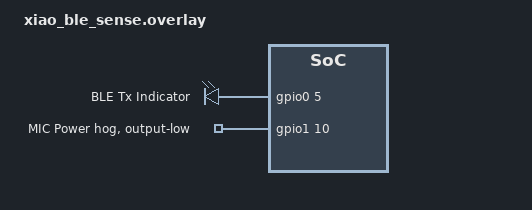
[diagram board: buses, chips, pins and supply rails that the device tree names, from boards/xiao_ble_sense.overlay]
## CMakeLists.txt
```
# SPDX-License-Identifier: MIT
cmake_minimum_required(VERSION 3.20)
find_package(Zephyr REQUIRED HINTS $ENV{ZEPHYR_BASE})
project(bthome_imu)
target_sources(app PRIVATE src/main.c)
```

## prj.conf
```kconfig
# ── Bluetooth ──────────────────────────────────────────────────────────────
CONFIG_BT=y
CONFIG_BT_PERIPHERAL=y
CONFIG_BT_DEVICE_NAME="MAKE-IMU"
# bt_disable() wird im Low-Power-Loop genutzt (kein CTRL_DISABLE-Flag nötig)

# ── BThome V2 library ───────────────────────────────────────────────────────
CONFIG_BTHOME_V2=y

# ── Sensor framework ────────────────────────────────────────────────────────
CONFIG_SENSOR=y
CONFIG_I2C=y
CONFIG_LSM6DSL=y
CONFIG_LSM6DSL_ACCEL_ODR=4
CONFIG_LSM6DSL_GYRO_ODR=4

# ── Logging ─────────────────────────────────────────────────────────────────
CONFIG_LOG=y
CONFIG_LOG_MODE_IMMEDIATE=y

# ── Stack ────────────────────────────────────────────────────────────────────
# bt_enable()/bt_disable() im Loop braucht etwas mehr Stack als einmalige Init
CONFIG_MAIN_STACK_SIZE=3072
CONFIG_BT_RX_STACK_SIZE=1024
CONFIG_IDLE_STACK_SIZE=512

# ── Power Management ─────────────────────────────────────────────────────────
# PM_DEVICE: für IMU SUSPEND/RESUME via pm_device_action_run()
CONFIG_PM_DEVICE=y
# KEIN PM_DEVICE_RUNTIME: würde Work-Queue-Threads erzeugen → Stack-Overhead
CONFIG_PM_DEVICE_RUNTIME=n
# Tickless Kernel: nRF52840 schläft in WFE während k_sleep() → ~3 µA SoC
CONFIG_TICKLESS_KERNEL=y
```

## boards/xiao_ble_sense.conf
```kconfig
# XIAO nRF52840 Sense — board-specific config for 200_bthome_imu

# ── LFCLK: RC-Oszillator ─────────────────────────────────────────────────────
# XIAO nRF52840 hat keinen externen 32.768-kHz-Quarz → RC-Oszillator ist Pflicht.
CONFIG_CLOCK_CONTROL_NRF_K32SRC_RC=y

# ── Serial / USB / Log: ausschalten für Batteriebetrieb ──────────────────────────
#
# Das Board-Defconfig (xiao_ble_defconfig) aktiviert USB + UART + CONSOLE.
# Alle drei halten den HFCLK und müssen deaktiviert werden:
#
#   USB_DEVICE_STACK=y  → ~1.1 mA  (USB-SOF-IRQ alle 1 ms hält HFXO)
#   SERIAL=y            → ~1.0 mA  (UARTE0 hält den HFINT-Oszillator)
#
CONFIG_USB_DEVICE_STACK=n
CONFIG_USB_CDC_ACM=n
CONFIG_SERIAL=n
CONFIG_CONSOLE=n
CONFIG_UART_CONSOLE=n
CONFIG_LOG=n

# ── MPSL / HFCLK – wichtiger Hinweis ───────────────────────────────────────────
# CONFIG_BT_UNINIT_MPSL_ON_DISABLE wird hier NICHT gesetzt!
#
# Dieses Sample nutzt System ON / CPU asleep (WFI), KEIN System OFF.
# BT_UNINIT_MPSL_ON_DISABLE ruft mpsl_lib_uninit() auf, was den MPSL-Clock-
# Arbiter entfernt. Wenn danach die Zephyr-RC-Kalibrierung (~alle 4 s) feuert,
# gibt es keinen Arbiter mehr → HFCLK bleibt dauerhaft aktiv → ~400 µA Floor.
#
# Ohne BT_UNINIT_MPSL_ON_DISABLE: bt_disable() gibt HFCLK frei, MPSL bleibt
# initialisiert und verwaltet die RC-Kalibrierung korrekt.
# Ergebnis: CPU im WFI-Sleep → ~10–45 µA.

# ── NFCT-Pins als GPIO freigeben ─────────────────────────────────────────────
CONFIG_NFCT_PINS_AS_GPIOS=y

# ── GPIO-Regulator für IMU-Stromversorgung (P1.08) ───────────────────────────
CONFIG_REGULATOR=y

# ── BLE TX-Leistung begrenzen ─────────────────────────────────────────────────
# −20 dBm genügt für Heimanwendungen (≈10 m), spart ~1.5 mA vs. 0 dBm.
CONFIG_BT_CTLR_TX_PWR_MINUS_20=y
```

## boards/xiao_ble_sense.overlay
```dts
/* DTS-Overlay für Seeed XIAO nRF52840 Sense
 * Fügt einen imu0-Alias hinzu, damit main.c board-unabhängig bleibt.
 */
/ {
	aliases {
		imu0 = &lsm6ds3tr_c;
	};
};

/* ── QSPI-Flash: Peripheral deaktivieren ────────────────────────────────────
 * nrfx_qspi_init() hält HFCLK permanent (~200 µA im Leerlauf).
 * Bit-Bang DPD (0xB9) wird in main.c vor bt_enable() gesendet.
 * Der Flash bleibt danach in Deep Power-Down bis zum nächsten Power-Cycle. */
&qspi {
	status = "disabled";
};

/* ── Active Indicator: P0.05 (XIAO D5 / i2c1 SCL) ──────────────────────────────────
 * HIGH während des BLE-ADV-Fensters, LOW im Schlaf.
 * i2c1 (P0.04=SDA, P0.05=SCL) muss deaktiviert werden, um P0.05 als GPIO zu nutzen. */
&i2c1 {
	status = "disabled";
};

/ {
	active_ind: active_indicator {
		compatible = "gpio-leds";
		active0: active_0 {
			gpios = <&gpio0 5 GPIO_ACTIVE_HIGH>;
			label = "BLE Tx Indicator";
		};
	};

	aliases {
		active-indicator = &active0;
	};
};

/* ── Mikrofon-Versorgung abschalten (P1.10) ──────────────────────────────────────────
 * P1.10 = VCC_MIC Enable (active-HIGH). LOW = Mikrofon ausgeschaltet.
 * gpio-hog setzt den Pin beim Boot auf LOW → Mikrofon bleibt dauerhaft aus. */
&gpio1 {
	pwr-mic {
		gpio-hog;
		gpios = <10 GPIO_ACTIVE_HIGH>;
		output-low;
		line-name = "MIC Power";
	};
};
```

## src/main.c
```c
/* SPDX-License-Identifier: MIT */
/*
 * Copyright (c) 2026 Daniel Glaser
 *
 * BThome V2 IMU Sample
 * ====================
 * Liest den eingebauten 6-Achsen-IMU (LSM6DS3TR-C) des Seeed XIAO
 * nRF52840 Sense und sendet Beschleunigung (X/Y/Z) und Gyroskop (Z)
 * alle 5 Sekunden als BThome-V2-Advertising.
 *
 * Zwei sequenzielle BThome-Pakete (je ADV_BURST_MS/2 = 500 ms):
 *   Paket 1 — Objekte (ASC):
 *     0x00  Packet ID           uint8              2 B
 *     0x52  Gyroscope           uint16  0.001 °/s  3 B   Gesamt: 5 B
 *   Paket 2 — Objekte (ASC):
 *     0x00  Packet ID           uint8              2 B
 *     0x63  Acceleration axis   sint32  0.000001 m/s²   (3×) 15 B  Gesamt: 17 B
 *
 * Hintergrund: Ältere bthome-ble-Versionen in HA haben Probleme mit
 * dreifachen 0x63-Einträgen im selben Paket. Splitting umgeht das Problem:
 * HA legt das Gerät via Paket 1 (bekannte IDs) an, Paket 2 ergänzt die
 * Accel-Entities. Beide Pakete werden über die MAC-Adresse verknüpft.
 *
 * Takt:
 *   IMU aktiv → fetch → Paket 1 (500 ms) → Paket 2 (500 ms) → sleep 4 s
 *   Netto-Zykluszeit ≈ 5 s
 *
 * Sensor-Konvertierung:
 *   Beschleunigung: Zephyr sensor_value (m/s²) → sint32 (µm/s² = × 1e6)
 *   Gyroskop:       Zephyr sensor_value (rad/s) → uint16 (mdeg/s)
 *                   Formel: |val_urad/s| × 180000 / 3141593
 *
 * Build:
 *   west build -b xiao_ble_sense samples/200_bthome_imu
 *   oder: make 200-build BOARD=xiao_ble_sense
 */

#include <zephyr/kernel.h>
#include <zephyr/logging/log.h>
#include <zephyr/bluetooth/bluetooth.h>
#include <zephyr/bluetooth/hci.h>
#include <zephyr/drivers/gpio.h>
#include <zephyr/drivers/sensor.h>
#include <zephyr/pm/device.h>
#include <hal/nrf_gpio.h>
#include <math.h>

#include <bthome_v2/bthome_v2.h>

LOG_MODULE_REGISTER(bthome_imu, LOG_LEVEL_INF);

/* ── IMU-Regulator-Startup-Delay ────────────────────────────────────────
 * Der regulator-fixed-Treiber setzt P1.08 HIGH während regulator_fixed_init()
 * (SYS_INIT POST_KERNEL, Prio 75). In der regulator-boot-on-Code-Pfad wird
 * startup-delay-us NICHT abgewartet (nur im api->enable()-Pfad). Der
 * LSM6DSL-Treiber (Prio 90) würde sonst unmittelbar danach starten, bevor
 * der IMU die 3 ms Hochlaufzeit abgeschlossen hat.
 *
 * Lösung: SYS_INIT bei Prio 80 wartet 5 ms, bevor der Sensor-Treiber
 * bei Prio 90 initialisiert wird.
 */
static int imu_power_on_delay(void)
{
	/* 5 ms busy-wait: sicherer als k_sleep() während POST_KERNEL-Init */
	k_busy_wait(5000U);
	return 0;
}
SYS_INIT(imu_power_on_delay, POST_KERNEL, 80);

/* ── P25Q16H QSPI-Flash Deep Power-Down via GPIO Bit-Bang ──────────────── */
#define FLASH_PIN_MOSI  20u
#define FLASH_PIN_SCK   21u
#define FLASH_PIN_CSN   25u
#define FLASH_CMD_DPD   0xB9u

static void flash_deep_power_down(void)
{
	nrf_gpio_cfg_output(FLASH_PIN_CSN);
	nrf_gpio_cfg_output(FLASH_PIN_SCK);
	nrf_gpio_cfg_output(FLASH_PIN_MOSI);
	nrf_gpio_pin_set(FLASH_PIN_CSN);
	nrf_gpio_pin_clear(FLASH_PIN_SCK);
	nrf_gpio_pin_clear(FLASH_PIN_MOSI);
	nrf_gpio_pin_clear(FLASH_PIN_CSN);
	for (int i = 7; i >= 0; i--) {
		nrf_gpio_pin_write(FLASH_PIN_MOSI, (FLASH_CMD_DPD >> i) & 1u);
		nrf_gpio_pin_set(FLASH_PIN_SCK);
		nrf_gpio_pin_clear(FLASH_PIN_SCK);
	}
	nrf_gpio_pin_set(FLASH_PIN_CSN);
	k_busy_wait(10u);
}

/* ── IMU-Gerät ─────────────────────────────────────────────────────────── */
#if DT_NODE_HAS_STATUS(DT_ALIAS(imu0), okay)
static const struct device *const imu = DEVICE_DT_GET(DT_ALIAS(imu0));
#define HAS_IMU 1
#else
#define HAS_IMU 0
#warning "kein imu0-Alias definiert – Sensor-Ausgabe wird simuliert"
#endif

/* ── Active Indicator (P0.05 = D5): HIGH während BLE aktiv ─────────────── */
#if DT_NODE_HAS_STATUS(DT_ALIAS(active_indicator), okay)
static const struct gpio_dt_spec led_tx =
	GPIO_DT_SPEC_GET(DT_ALIAS(active_indicator), gpios);
#define HAS_LED_TX 1
#else
#define HAS_LED_TX 0
#endif

/* ── Timing ────────────────────────────────────────────────────────────── */
/** Aktive Advertising-Dauer pro Zyklus (ms) */
#define ADV_BURST_MS     1000U
/** Schlafzeit nach dem Advertising (ms), ergibt ~5 s Gesamtperiode */
#define SLEEP_MS         4000U

/* ── BLE-Parameter ─────────────────────────────────────────────────────── */
#define ADV_INTERVAL_MS  200U
#define ADV_INT          (ADV_INTERVAL_MS * 8U / 5U)  /* BLE-Einheiten */

static const struct bt_le_adv_param adv_param =
	BT_LE_ADV_PARAM_INIT(BT_LE_ADV_OPT_USE_IDENTITY,
			     ADV_INT, ADV_INT, NULL);

/* ── BThome-Kontext ─────────────────────────────────────────────────────── */
static struct bthome_v2_ctx bthome;   /* Paket 1: pkt_id + gyroscope */
static struct bthome_v2_ctx bthome2;  /* Paket 2: pkt_id + acceleration X/Y/Z */
/* ad[0] = Flags, ad[1] = Service Data (kein Name im ADV → Scan Response) */
static struct bt_data ad[2];

/* ── Scan Response: Gerätename ──────────────────────────────────────────── */
static struct bt_data sd[] = {
	BT_DATA(BT_DATA_NAME_COMPLETE,
		CONFIG_BT_DEVICE_NAME,
		sizeof(CONFIG_BT_DEVICE_NAME) - 1),
};

/* ── Paketzhähler ──────────────────────────────────────────────────────── */
static uint8_t pkt_id;

/* ── Sensor-Konvertierungshelfer ────────────────────────────────────────── */

/**
 * Wandelt einen Zephyr sensor_value (val1 + val2/1e6 in m/s²)
 * in den BThome-0x63-Rohwert (sint32, × 1e-6 m/s²) um.
 */
static int32_t accel_to_micro_ms2(const struct sensor_value *v)
{
	return (int32_t)((int64_t)v->val1 * 1000000 + v->val2);
}

/**
 * Wandelt einen Zephyr sensor_value (rad/s) in milli-Grad/s (uint16) um.
 * Klammerung auf uint16-Wertebereich (max 65535 mdeg/s = 65.535 °/s).
 */
static uint16_t gyro_to_milli_degs(const struct sensor_value *v)
{
	/* Gesamtwert in µrad/s */
	int64_t uras = (int64_t)v->val1 * 1000000 + v->val2;
	/* µrad/s → mdeg/s: × 180000 / 3141593 */
	int64_t mdeg = uras * 180000LL / 3141593LL;

	if (mdeg < 0) {
		mdeg = -mdeg;
	}
	if (mdeg > 65535) {
		mdeg = 65535;
	}
	return (uint16_t)mdeg;
}

/**
 * Berechnet den euklidischen Betrag |ω| = √(gx² + gy² + gz²) in mdeg/s.
 * Da BThome-Gyro (0x52) vorzeichenlos ist, ist der Vektorbetrag die
 * semantisch korrekte Darstellung der Rotationsgeschwindigkeit.
 *
 * Hinweis: Bei gleichzeitiger Vollaussteuerung aller 3 Achsen kann
 * |ω| ≤ √3 × 65535 ≈ 113 511 mdeg/s > UINT16_MAX → Sättigung bei 65535.
 */
static uint16_t gyro_magnitude(uint16_t gx, uint16_t gy, uint16_t gz)
{
	uint64_t sq = (uint64_t)gx * gx + (uint64_t)gy * gy + (uint64_t)gz * gz;
	uint32_t mag = (uint32_t)sqrtf((float)sq);

	return (mag > UINT16_MAX) ? UINT16_MAX : (uint16_t)mag;
}

/* ── Advertising-Helfer ─────────────────────────────────────────────────── */
/*
 * Zwei sequenzielle BThome-Pakete je ADV_BURST_MS/2:
 *   Paket 1: pkt_id + gyroscope  → HA kann Gerät sofort anlegen
 *   Paket 2: pkt_id + accel X/Y/Z → Accel-Entities werden ergänzt
 * HA assoziiert beide Pakete über die MAC-Adresse zum selben Gerät.
 */
static void adv_send(int32_t ax, int32_t ay, int32_t az, uint16_t gz)
{
	int err;

	/* ── Paket 1: pkt_id + gyroscope (ADV_BURST_MS/2) ── */
	bt_le_adv_stop();
	bthome_v2_clear(&bthome);
	bthome_v2_add_packet_id(&bthome, pkt_id++);    /* 0x00 */
	bthome_v2_add_gyroscope(&bthome, gz);          /* 0x52 */
	bthome_v2_encode(&bthome);
	bthome_v2_get_bt_data(&bthome, &ad[1]);

	err = bt_le_adv_start(&adv_param, ad, ARRAY_SIZE(ad),
			      sd, ARRAY_SIZE(sd));
	if (err) {
		LOG_ERR("bt_le_adv_start (gyro): %d", err);
		return;
	}
	k_msleep(ADV_BURST_MS / 2U);
	bt_le_adv_stop();

	/* ── Paket 2: pkt_id + acceleration X/Y/Z (läuft bis main bt_le_adv_stop) ── */
	bthome_v2_clear(&bthome2);
	bthome_v2_add_packet_id(&bthome2, pkt_id++);    /* 0x00 */
	bthome_v2_add_acceleration_axis(&bthome2, ax);  /* 0x63 */
	bthome_v2_add_acceleration_axis(&bthome2, ay);  /* 0x63 */
	bthome_v2_add_acceleration_axis(&bthome2, az);  /* 0x63 */
	bthome_v2_encode(&bthome2);
	bthome_v2_get_bt_data(&bthome2, &ad[1]);

	err = bt_le_adv_start(&adv_param, ad, ARRAY_SIZE(ad),
			      sd, ARRAY_SIZE(sd));
	if (err) {
		LOG_ERR("bt_le_adv_start (accel): %d", err);
		return;
	}

	LOG_INF("ADV pkt=%u/%u  ax=%d ay=%d az=%d µm/s²  gz=%u mdeg/s",
		pkt_id - 2, pkt_id - 1, ax, ay, az, gz);
}

/* ── main ──────────────────────────────────────────────────────────────── */
int main(void)
{
	LOG_INF("=== BThome IMU Sample ===");

	/* Flash in Deep Power-Down, bevor HFXO durch BLE gestartet wird */
	flash_deep_power_down();

#if HAS_IMU
	if (!device_is_ready(imu)) {
		LOG_ERR("IMU nicht bereit: %s", imu->name);
		return -ENODEV;
	}
	LOG_INF("IMU bereit: %s", imu->name);
#endif

	/* BThome-Kontext + Flags-AD */
	bthome_v2_init(&bthome,  false, false);
	bthome_v2_init(&bthome2, false, false);
	ad[0] = (struct bt_data) BT_DATA_BYTES(BT_DATA_FLAGS,
			BT_LE_AD_GENERAL | BT_LE_AD_NO_BREDR);

	/* Active Indicator initialisieren (P0.05 = D5, active-high, initial LOW) */
#if HAS_LED_TX
	if (gpio_is_ready_dt(&led_tx)) {
		gpio_pin_configure_dt(&led_tx, GPIO_OUTPUT_INACTIVE);
	}
#endif

	/* Bluetooth einmalig aktivieren */
	int ret = bt_enable(NULL);

	if (ret) {
		LOG_ERR("bt_enable: %d", ret);
		return ret;
	}
	LOG_INF("Bluetooth bereit");

	/*
	 * Hauptschleife: alle ~5 s messen und advertisen
	 *
	 * Low-Power-Strategie:
	 *   1. BLE nach dem ADV-Fenster mit bt_disable() vollständig abschalten
	 *      → SoftDevice Controller + HFXO gehen aus → spart ~2.5 mA
	 *   2. IMU per PM in Power-Down versetzen (CTRL1_XL/CTRL2_G ODR=0)
	 *      → spart ~0.9 mA, ODR wird beim Resume automatisch wiederhergestellt
	 *   3. TICKLESS_KERNEL lässt den nRF52840 während k_sleep() in
	 *      System Idle (WFE) verweilen → nur ~3 µA SoC-Strom
	 *
	 * Stromverbrauch (geschätzt, XIAO BLE Sense):
	 *   ADV-Phase (1 s):    ~6 mA  (BLE TX + IMU aktiv)
	 *   Schlaf-Phase (4 s): ~45 µA (HW-Floor: Charge-IC + LDO)
	 *   Mittlerer Strom:    ~1.4 mA → CR2032  ~7 Tage
	 *                               → 2× AA  ~75 Tage
	 */
	while (true) {
		int32_t ax = 0, ay = 0, az = 0;
		uint16_t gx = 0, gy = 0, gz = 0, gmag = 0;

#if HAS_IMU
		ret = sensor_sample_fetch(imu);
		if (ret) {
			LOG_WRN("sensor_sample_fetch: %d", ret);
		} else {
			struct sensor_value sv_ax, sv_ay, sv_az;
			struct sensor_value sv_gx, sv_gy, sv_gz;

			sensor_channel_get(imu, SENSOR_CHAN_ACCEL_X, &sv_ax);
			sensor_channel_get(imu, SENSOR_CHAN_ACCEL_Y, &sv_ay);
			sensor_channel_get(imu, SENSOR_CHAN_ACCEL_Z, &sv_az);
			sensor_channel_get(imu, SENSOR_CHAN_GYRO_X,  &sv_gx);
			sensor_channel_get(imu, SENSOR_CHAN_GYRO_Y,  &sv_gy);
			sensor_channel_get(imu, SENSOR_CHAN_GYRO_Z,  &sv_gz);

			ax = accel_to_micro_ms2(&sv_ax);
			ay = accel_to_micro_ms2(&sv_ay);
			az = accel_to_micro_ms2(&sv_az);
			gx = gyro_to_milli_degs(&sv_gx);
			gy = gyro_to_milli_degs(&sv_gy);
			gz = gyro_to_milli_degs(&sv_gz);
			gmag = gyro_magnitude(gx, gy, gz);

			LOG_INF("Accel:    X=%d Y=%d Z=%d µm/s²", ax, ay, az);
			LOG_INF("Gyro XYZ: X=%u Y=%u Z=%u mdeg/s", gx, gy, gz);
			LOG_INF("Gyro |ω|: %u mdeg/s  (%u.%03u °/s)  → BThome",
				gmag, gmag / 1000U, gmag % 1000U);
		}
#endif

		/* Active Indicator HIGH: BLE-Fenster beginnt */
#if HAS_LED_TX
		gpio_pin_set_dt(&led_tx, 1);
#endif

		adv_send(ax, ay, az, gmag);

		/* Zweites Paket (accel) läuft für die zweite Hälfte des ADV-Fensters */
		k_sleep(K_MSEC(ADV_BURST_MS / 2U));

		/* ── Schlafphase: alle Verbraucher abschalten ── */

		/* bt_le_adv_stop() muss VOR bt_disable() gerufen werden.
		 * Bei Fehler wird trotzdem weitergemacht – bt_disable() räumt auf. */
		ret = bt_le_adv_stop();
		if (ret && ret != -EALREADY) {
			LOG_WRN("bt_le_adv_stop: %d", ret);
		}

		/* IMU in Hardware-Power-Down (ODR → 0, ~6 µA Ruhestrom) */
#if HAS_IMU
		ret = pm_device_action_run(imu, PM_DEVICE_ACTION_SUSPEND);
		if (ret && ret != -ENOTSUP && ret != -EALREADY) {
			LOG_WRN("IMU SUSPEND: %d", ret);
		}
#endif

		/* Active Indicator LOW: BLE-Fenster abgeschlossen */
#if HAS_LED_TX
		gpio_pin_set_dt(&led_tx, 0);
#endif

		/* BLE-Stack + HFXO vollständig abschalten (~2.5 mA gespart).
		 * bt_disable() gibt HFCLK frei; MPSL bleibt initialisiert
		 * (kein BT_UNINIT_MPSL_ON_DISABLE!) → RC-Kalibrierung läuft korrekt. */
		ret = bt_disable();
		if (ret) {
			LOG_ERR("bt_disable: %d – sleep skipped", ret);
			/* HFXO nicht freigegeben → nicht schlafen, sofort neu starten */
			goto wake_up;
		}

		/* nRF52840 schläft tickless (WFE) → ~3 µA SoC-Strom */
		k_sleep(K_MSEC(SLEEP_MS));

wake_up:
		/* ── Aufwecken: Verbraucher wieder einschalten ── */

		/* BLE neu initialisieren (~100–300 ms HFXO-Startzeit einkalkuliert) */
		ret = bt_enable(NULL);
		if (ret) {
			LOG_ERR("bt_enable (loop): %d", ret);
			/* Ohne BLE weiter laufen – nächste Iteration versucht es erneut */
		}

		/* IMU aufwecken: Treiber stellt gespeicherten ODR wieder her */
#if HAS_IMU
		ret = pm_device_action_run(imu, PM_DEVICE_ACTION_RESUME);
		if (ret && ret != -ENOTSUP && ret != -EALREADY) {
			LOG_WRN("IMU RESUME: %d", ret);
		}
		/* 10 ms warten: sicherer als 2 ms (1/ODR bei 104 Hz = 9.6 ms) */
		k_msleep(10);
#endif
	}

	return 0;
}
```
